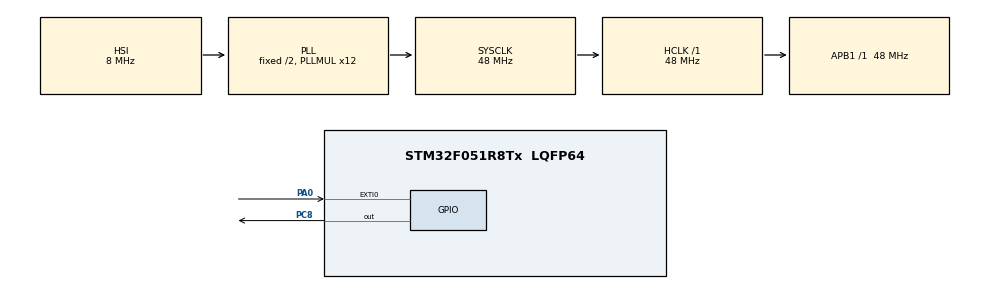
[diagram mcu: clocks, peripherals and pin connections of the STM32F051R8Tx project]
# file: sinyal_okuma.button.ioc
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Mcu.Family=STM32F0
Mcu.Name=STM32F051R8Tx
Mcu.Package=LQFP64
NVIC.EXTI0_1_IRQn=true\:0\:0\:false\:false\:true\:true\:true\:true
NVIC.TIM2_IRQn=true\:0\:0\:false\:false\:true\:true\:true\:true
PA0.Signal=GPXTI0
PA13.Mode=Serial_Wire
PA13.Signal=SYS_SWDIO
PA14.Mode=Serial_Wire
PA14.Signal=SYS_SWCLK
PC8.Signal=GPIO_Output
PF0-OSC_IN.Mode=HSE-External-Oscillator
PF0-OSC_IN.Signal=RCC_OSC_IN
PF1-OSC_OUT.Mode=HSE-External-Oscillator
PF1-OSC_OUT.Signal=RCC_OSC_OUT
ProjectManager.HeapSize=0x200
ProjectManager.StackSize=0x400
ProjectManager.TargetToolchain=STM32CubeIDE
RCC.AHBFreq_Value=48000000
RCC.APB1Freq_Value=48000000
RCC.APB1TimFreq_Value=48000000
RCC.HCLKFreq_Value=48000000
RCC.PLLMUL=RCC_PLL_MUL12
RCC.SYSCLKFreq_VALUE=48000000
RCC.SYSCLKSource=RCC_SYSCLKSOURCE_PLLCLK
TIM2.Period=50-1
TIM2.Prescaler=48000-1
VP_TIM2_VS_ClockSourceINT.Mode=Internal
board=custom

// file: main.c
/* USER CODE BEGIN Header */
/**
  ******************************************************************************
  * @file           : main.c
  * @brief          : Main program body
  ******************************************************************************
  * @attention
  *
  * Copyright (c) 2024 STMicroelectronics.
  * All rights reserved.
  *
  * This software is licensed under terms that can be found in the LICENSE file
  * in the root directory of this software component.
  * If no LICENSE file comes with this software, it is provided AS-IS.
  *
  ******************************************************************************
  */
/* USER CODE END Header */
#include "main.h"

/* USER CODE BEGIN PD */
typedef enum {
	Btn_NULL,
	Btn_STOP,
    Btn_START
} Btn_State;
/* USER CODE END PD */

TIM_HandleTypeDef htim2;

/* USER CODE BEGIN PV */
Btn_State state = Btn_NULL;
/* USER CODE END PV */

void SystemClock_Config(void);
static void MX_GPIO_Init(void);
static void MX_TIM2_Init(void);
/* USER CODE BEGIN PFP */
Btn_State GetBtnState(void);
/* USER CODE END PFP */

/* USER CODE BEGIN 0 */
void HAL_GPIO_EXTI_Callback(uint16_t GPIO_Pin)
{
    if(GPIO_Pin == GPIO_PIN_0)
    {
        if(__HAL_TIM_GET_COUNTER(&htim2) == 0)
        {
            HAL_TIM_Base_Start_IT(&htim2);
        }
    }
}

void HAL_TIM_PeriodElapsedCallback(TIM_HandleTypeDef *htim)
{
    if(htim->Instance == TIM2)
    {
    	state = GetBtnState();
        HAL_TIM_Base_Stop_IT(&htim2);
        __HAL_TIM_SET_COUNTER(&htim2, 0);
    }
}
/* USER CODE END 0 */

int main(void)
{

  /* MCU Configuration--------------------------------------------------------*/

  /* Reset of all peripherals, Initializes the Flash interface and the Systick. */
  HAL_Init();

  /* Configure the system clock */
  SystemClock_Config();

  /* Initialize all configured peripherals */
  MX_GPIO_Init();
  MX_TIM2_Init();

  /* Infinite loop */
  while (1)
  {

    /* USER CODE BEGIN 3 */
	  if(state == Btn_STOP)
	  {
		  HAL_GPIO_WritePin(GPIOC, GPIO_PIN_8, GPIO_PIN_RESET);
	  }
	  else if(state == Btn_START)
	  {
		  HAL_GPIO_WritePin(GPIOC, GPIO_PIN_8, GPIO_PIN_SET);
	  }
  }
  /* USER CODE END 3 */
}

void SystemClock_Config(void)
{
  RCC_OscInitTypeDef RCC_OscInitStruct = {0};
  RCC_ClkInitTypeDef RCC_ClkInitStruct = {0};

  /** Initializes the RCC Oscillators according to the specified parameters
  * in the RCC_OscInitTypeDef structure.
  */
  RCC_OscInitStruct.OscillatorType = RCC_OSCILLATORTYPE_HSI;
  RCC_OscInitStruct.HSIState = RCC_HSI_ON;
  RCC_OscInitStruct.HSICalibrationValue = RCC_HSICALIBRATION_DEFAULT;
  RCC_OscInitStruct.PLL.PLLState = RCC_PLL_ON;
  RCC_OscInitStruct.PLL.PLLSource = RCC_PLLSOURCE_HSI;
  RCC_OscInitStruct.PLL.PLLMUL = RCC_PLL_MUL12;
  RCC_OscInitStruct.PLL.PREDIV = RCC_PREDIV_DIV1;
  if (HAL_RCC_OscConfig(&RCC_OscInitStruct) != HAL_OK)
  {
    Error_Handler();
  }

  /** Initializes the CPU, AHB and APB buses clocks
  */
  RCC_ClkInitStruct.ClockType = RCC_CLOCKTYPE_HCLK|RCC_CLOCKTYPE_SYSCLK
                              |RCC_CLOCKTYPE_PCLK1;
  RCC_ClkInitStruct.SYSCLKSource = RCC_SYSCLKSOURCE_PLLCLK;
  RCC_ClkInitStruct.AHBCLKDivider = RCC_SYSCLK_DIV1;
  RCC_ClkInitStruct.APB1CLKDivider = RCC_HCLK_DIV1;

  if (HAL_RCC_ClockConfig(&RCC_ClkInitStruct, FLASH_LATENCY_1) != HAL_OK)
  {
    Error_Handler();
  }
}

static void MX_TIM2_Init(void)
{

  TIM_ClockConfigTypeDef sClockSourceConfig = {0};
  TIM_MasterConfigTypeDef sMasterConfig = {0};

  htim2.Instance = TIM2;
  htim2.Init.Prescaler = 48000-1;
  htim2.Init.CounterMode = TIM_COUNTERMODE_UP;
  htim2.Init.Period = 50-1;
  htim2.Init.ClockDivision = TIM_CLOCKDIVISION_DIV1;
  htim2.Init.AutoReloadPreload = TIM_AUTORELOAD_PRELOAD_DISABLE;
  if (HAL_TIM_Base_Init(&htim2) != HAL_OK)
  {
    Error_Handler();
  }
  sClockSourceConfig.ClockSource = TIM_CLOCKSOURCE_INTERNAL;
  if (HAL_TIM_ConfigClockSource(&htim2, &sClockSourceConfig) != HAL_OK)
  {
    Error_Handler();
  }
  sMasterConfig.MasterOutputTrigger = TIM_TRGO_RESET;
  sMasterConfig.MasterSlaveMode = TIM_MASTERSLAVEMODE_DISABLE;
  if (HAL_TIMEx_MasterConfigSynchronization(&htim2, &sMasterConfig) != HAL_OK)
  {
    Error_Handler();
  }

}

static void MX_GPIO_Init(void)
{
  GPIO_InitTypeDef GPIO_InitStruct = {0};

  /* GPIO Ports Clock Enable */
  __HAL_RCC_GPIOF_CLK_ENABLE();
  __HAL_RCC_GPIOA_CLK_ENABLE();
  __HAL_RCC_GPIOC_CLK_ENABLE();

  /*Configure GPIO pin Output Level */
  HAL_GPIO_WritePin(GPIOC, GPIO_PIN_8, GPIO_PIN_RESET);

  /*Configure GPIO pin : PA0 */
  GPIO_InitStruct.Pin = GPIO_PIN_0;
  GPIO_InitStruct.Mode = GPIO_MODE_IT_RISING;
  GPIO_InitStruct.Pull = GPIO_NOPULL;
  HAL_GPIO_Init(GPIOA, &GPIO_InitStruct);

  /*Configure GPIO pin : PC8 */
  GPIO_InitStruct.Pin = GPIO_PIN_8;
  GPIO_InitStruct.Mode = GPIO_MODE_OUTPUT_PP;
  GPIO_InitStruct.Pull = GPIO_NOPULL;
  GPIO_InitStruct.Speed = GPIO_SPEED_FREQ_LOW;
  HAL_GPIO_Init(GPIOC, &GPIO_InitStruct);

  /* EXTI interrupt init*/
  HAL_NVIC_SetPriority(EXTI0_1_IRQn, 0, 0);
  HAL_NVIC_EnableIRQ(EXTI0_1_IRQn);

}

/* USER CODE BEGIN 4 */
Btn_State GetBtnState(void) {

    static uint8_t buttoncounter = 0;

    if(HAL_GPIO_ReadPin(GPIOA, GPIO_PIN_0) == GPIO_PIN_SET)
       buttoncounter++;

    if (buttoncounter % 2 == 0){
    	return Btn_STOP;
    }else{
    	return Btn_START;
    }
}
/* USER CODE END 4 */

void Error_Handler(void)
{
  __disable_irq();
  while (1)
  {
  }
}
